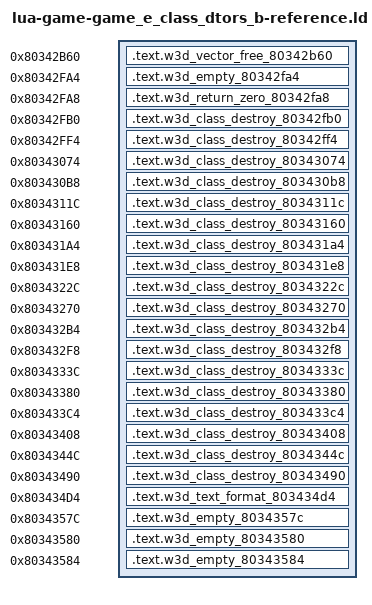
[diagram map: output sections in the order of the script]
/* Generated reference-only placements. All bodies are source-built. */
OUTPUT_FORMAT("elf32-powerpc")
OUTPUT_ARCH(powerpc)
ENTRY(w3d_vector_free_80342b60)
_SDA_BASE_ = 0x804b2540;
_SDA2_BASE_ = 0x804c2540;
w3d_object_base_destroy_80021468 = 0x80021468;
w3d_operator_delete_80015264 = 0x80015264;
w3d_text_vformat_802ed5e0 = 0x802ed5e0;
SECTIONS {
  .text.w3d_vector_free_80342b60 0x80342b60 : { *(.text.w3d_vector_free_80342b60) }
  .text.w3d_empty_80342fa4 0x80342fa4 : { *(.text.w3d_empty_80342fa4) }
  .text.w3d_return_zero_80342fa8 0x80342fa8 : { *(.text.w3d_return_zero_80342fa8) }
  .text.w3d_class_destroy_80342fb0 0x80342fb0 : { *(.text.w3d_class_destroy_80342fb0) }
  .text.w3d_class_destroy_80342ff4 0x80342ff4 : { *(.text.w3d_class_destroy_80342ff4) }
  .text.w3d_class_destroy_80343074 0x80343074 : { *(.text.w3d_class_destroy_80343074) }
  .text.w3d_class_destroy_803430b8 0x803430b8 : { *(.text.w3d_class_destroy_803430b8) }
  .text.w3d_class_destroy_8034311c 0x8034311c : { *(.text.w3d_class_destroy_8034311c) }
  .text.w3d_class_destroy_80343160 0x80343160 : { *(.text.w3d_class_destroy_80343160) }
  .text.w3d_class_destroy_803431a4 0x803431a4 : { *(.text.w3d_class_destroy_803431a4) }
  .text.w3d_class_destroy_803431e8 0x803431e8 : { *(.text.w3d_class_destroy_803431e8) }
  .text.w3d_class_destroy_8034322c 0x8034322c : { *(.text.w3d_class_destroy_8034322c) }
  .text.w3d_class_destroy_80343270 0x80343270 : { *(.text.w3d_class_destroy_80343270) }
  .text.w3d_class_destroy_803432b4 0x803432b4 : { *(.text.w3d_class_destroy_803432b4) }
  .text.w3d_class_destroy_803432f8 0x803432f8 : { *(.text.w3d_class_destroy_803432f8) }
  .text.w3d_class_destroy_8034333c 0x8034333c : { *(.text.w3d_class_destroy_8034333c) }
  .text.w3d_class_destroy_80343380 0x80343380 : { *(.text.w3d_class_destroy_80343380) }
  .text.w3d_class_destroy_803433c4 0x803433c4 : { *(.text.w3d_class_destroy_803433c4) }
  .text.w3d_class_destroy_80343408 0x80343408 : { *(.text.w3d_class_destroy_80343408) }
  .text.w3d_class_destroy_8034344c 0x8034344c : { *(.text.w3d_class_destroy_8034344c) }
  .text.w3d_class_destroy_80343490 0x80343490 : { *(.text.w3d_class_destroy_80343490) }
  .text.w3d_text_format_803434d4 0x803434d4 : { *(.text.w3d_text_format_803434d4) }
  .text.w3d_empty_8034357c 0x8034357c : { *(.text.w3d_empty_8034357c) }
  .text.w3d_empty_80343580 0x80343580 : { *(.text.w3d_empty_80343580) }
  .text.w3d_empty_80343584 0x80343584 : { *(.text.w3d_empty_80343584) }
  /DISCARD/ : { *(.text*) *(.rodata*) *(.data*) *(.bss*) *(.sdata*) *(.sbss*) *(.comment) }
}
